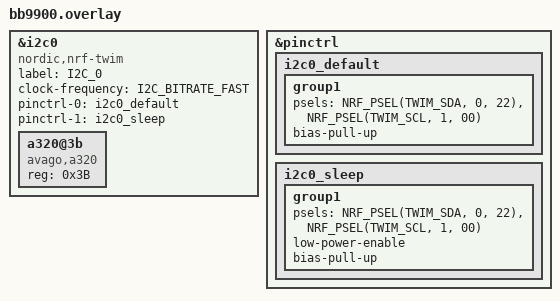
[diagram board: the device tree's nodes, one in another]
&i2c0 {
    a320@3b {
        compatible = "avago,a320";
        status = "okay";
        reg = <0x3B>;
    };
    
	label = "I2C_0";
	compatible = "nordic,nrf-twim";
	status = "okay";
	clock-frequency = <I2C_BITRATE_FAST>; 
	pinctrl-0 = <&i2c0_default>;
	pinctrl-1 = <&i2c0_sleep>;
	pinctrl-names = "default", "sleep";
};

&pinctrl {
    i2c0_default: i2c0_default {
		group1 {
			psels = <NRF_PSEL(TWIM_SDA, 0, 22)>,
				<NRF_PSEL(TWIM_SCL, 1, 00)>;
			bias-pull-up;
		};
	};
	i2c0_sleep: i2c0_sleep {
		group1 {
			psels = <NRF_PSEL(TWIM_SDA, 0, 22)>,
				<NRF_PSEL(TWIM_SCL, 1, 00)>;
			low-power-enable;
			bias-pull-up;
		};
	};
};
